# R7KA8P1AD register map
Vendor: Renesas Electronics Corporation; Series: RA8; File version: 1.10.02
CPU: CM85 r0p2, little endian, MPU, FPU, VTOR, 4 interrupt priority bits, 96 interrupts
Registers are 32-bit, read-write, reset 0x0 unless marked. A register's access mark holds for its fields unless they carry their own. Offsets are from the block's base; [hi:lo] are bit positions; {n}, {i} and the like mark numbered series; 'fields as' and 'values as' point back to an identical list; <NAME> marks a mode.

## BUS — Bus Control
Base 0x40003000
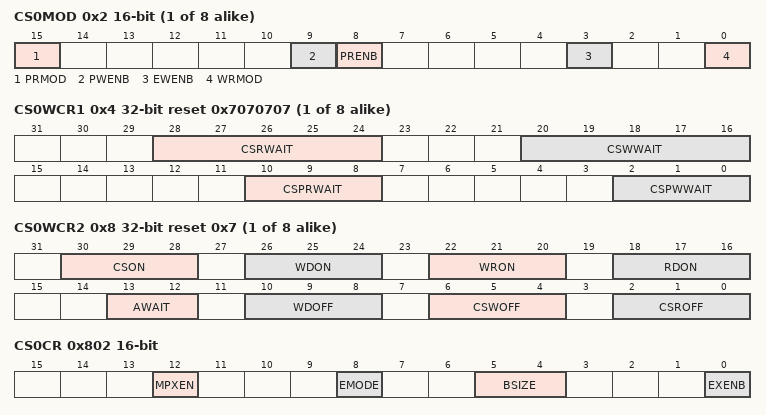
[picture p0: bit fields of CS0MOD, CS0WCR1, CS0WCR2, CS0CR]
{0x2+0x10*i} CS{i}MOD (i=0..7) 16-bit — CS{i} Mode Register (n = 0 to 7)
  [15] PRMOD — Page Read Access Mode Select
    0=Normal access compatible mode; 1=External data read continuous assertion mode
  [9] PWENB — Page Write Access Enable
    0=Disabled; 1=Enabled
  [8] PRENB — Page Read Access Enable
    0=Disabled; 1=Enabled
  [3] EWENB — External Wait Enable
    0=Disabled; 1=Enabled
  [0] WRMOD — Write Access Mode Select
    0=Byte strobe mode; 1=Single-write strobe mode
{0x4+0x10*i} CS{i}WCR1 (i=0..7) reset 0x7070707 — CS{i} Wait Control Register 1 (n = 0 to 7)
  [28:24] CSRWAIT — Normal Read Cycle Wait Select
  [20:16] CSWWAIT — Normal Write Cycle Wait Select
  [10:8] CSPRWAIT — Page Read Cycle Wait Select
  [2:0] CSPWWAIT — Page Write Cycle Wait Select
{0x8+0x10*i} CS{i}WCR2 (i=0..7) reset 0x7 — CS{i} Wait Control Register 2 (n = 0 to 7)
  [30:28] CSON — CS Assert Wait Select
  [26:24] WDON — Write Data Output Wait Select
  [22:20] WRON — WR Assert Wait Select
  [18:16] RDON — RD Assert Wait Select
  [13:12] AWAIT — Address Cycle Wait Select
  [10:8] WDOFF — Write Data Output Extension Cycle Select
  [6:4] CSWOFF — Write Access CS Extension Cycle Select
  [2:0] CSROFF — Read Access CS Extension Cycle Select
0x802 CS0CR 16-bit — CS0 Control Register
  [12] MPXEN — Address/Data Multiplexed I/O Interface Select
    0=Separate bus interface is selected for area n; 1=Address/data multiplexed I/O interface is selected for area n
  [8] EMODE — Endian Mode
    0=Little endian; 1=Big endian
  [5:4] BSIZE — External Bus Width Select
    0=16-bit bus space; 1=32-bit bus space; 2=8-bit bus space; other=Others (Setting prohibited)
  [0] EXENB — Operation Enable
    0=Disable operation; 1=Enable operation
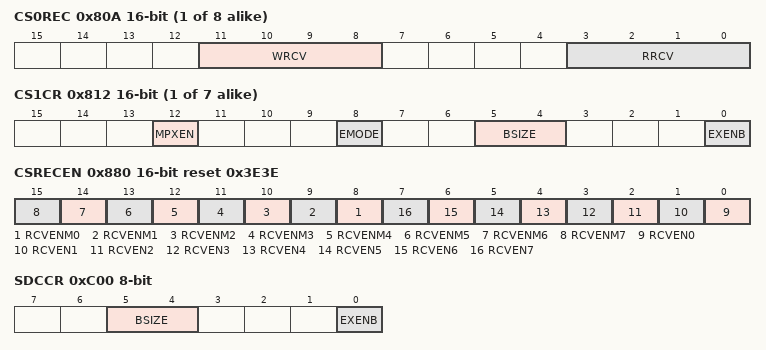
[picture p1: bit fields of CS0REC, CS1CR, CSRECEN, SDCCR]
{0x80A+0x10*i} CS{i}REC (i=0..7) 16-bit — CS{i} Recovery Cycle Register (n = 0 to 7)
  [11:8] WRCV — Write Recovery
  [3:0] RRCV — Read Recovery
{0x802+0x10*i} CS{i}CR (i=1..7) 16-bit — CS{i} Control Register
  fields as CS0CR
0x880 CSRECEN 16-bit reset 0x3E3E — CS Recovery Cycle Insertion Enable Register
  [all] fields
    0=Disabled; 1=Enabled
  [n+8] RCVENM{n} (n=0..7) — Multiplexed Bus Recovery Cycle Insertion Enable {n}
  [n] RCVEN{n} (n=0..7) — Separate Bus Recovery Cycle Insertion Enable {n}
0xC00 SDCCR 8-bit — SDC Control Register
  [5:4] BSIZE — SDRAM Bus Width Select
    values as CS0CR.BSIZE
  [0] EXENB — Operation Enable
    0=Disable; 1=Enable
0xC01 SDCMOD 8-bit — SDC Mode Register
  [0] EMODE — Endian Mode
    0=Little endian; 1=Big endian
0xC02 SDAMOD 8-bit — SDRAM Access Mode Register
  [0] BE — Continuous Access Enable
    0=Continuous access is disabled; 1=Continuous access is enabled
0xC10 SDSELF 8-bit — SDRAM Self-Refresh Control Register
  [0] SFEN — SDRAM Self-Refresh Enable
    0=Disable; 1=Enable
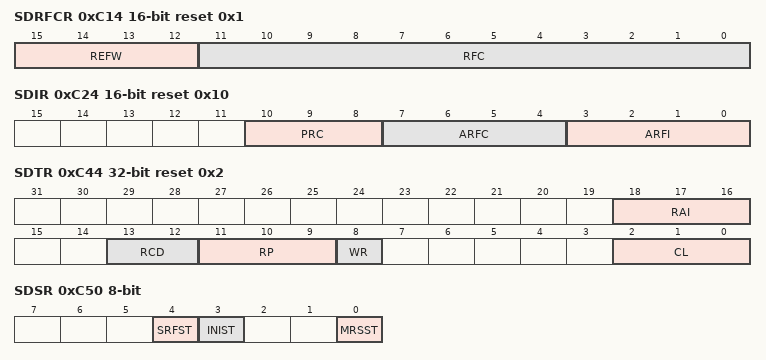
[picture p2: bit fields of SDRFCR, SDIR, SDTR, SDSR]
0xC14 SDRFCR 16-bit reset 0x1 — SDRAM Refresh Control Register
  [15:12] REFW — Auto-Refresh Cycle/Self-Refresh Clearing Cycle Count Setting
  [11:0] RFC — Auto-Refresh Request Interval Setting
0xC16 SDRFEN 8-bit — SDRAM Auto-Refresh Control Register
  [0] RFEN — Auto-Refresh Operation Enable
    0=Disable; 1=Enable
0xC20 SDICR 8-bit — SDRAM Initialization Sequence Control Register
  [0] INIRQ — Initialization Sequence Start
    0=Invalid; 1=Start initialization sequence
0xC24 SDIR 16-bit reset 0x10 — SDRAM Initialization Register
  [10:8] PRC — Initialization Precharge Cycle Count
  [7:4] ARFC — Initialization Auto-Refresh Count
  [3:0] ARFI — Initialization Auto-Refresh Interval
0xC40 SDADR 8-bit — SDRAM Address Register
  [1:0] MXC — Address Multiplex Select
    {v}={v+8}-bit shift (v=0..3)
0xC44 SDTR reset 0x2 — SDRAM Timing Register
  [18:16] RAI — Row Active Interval
    0=1 cycle; {v}={v+1} cycles (v=1..6); 7=Setting prohibited
  [13:12] RCD — Row Column Latency
    0=1 cycle; 1=2 cycles; 2=3 cycles; 3=4 cycles
  [11:9] RP — Row Precharge Interval
    0=1 cycle; {v}={v+1} cycles (v=1..7)
  [8] WR — Write Recovery Interval
    0=1 cycle; 1=2 cycles
  [2:0] CL — SDRAMC Column Latency
    0=Setting prohibited; 1=1 cycle; 2=2 cycles; 3=3 cycles; other=Others (Setting prohibited)
0xC48 SDMOD 16-bit — SDRAM Mode Register
  [14:0] MR — Mode Register Setting
0xC50 SDSR 8-bit ro — SDRAM Status Register
  [4] SRFST — Self-Refresh Transition/Recovery Status
    0=Transition/recovery not in progress; 1=Transition/recovery in progress
  [3] INIST — Initialization Status
    0=Initialization sequence not in progress; 1=Initialization sequence in progress
  [0] MRSST — Mode Register Setting Status
    0=Mode register setting not in progress; 1=Mode register setting in progress
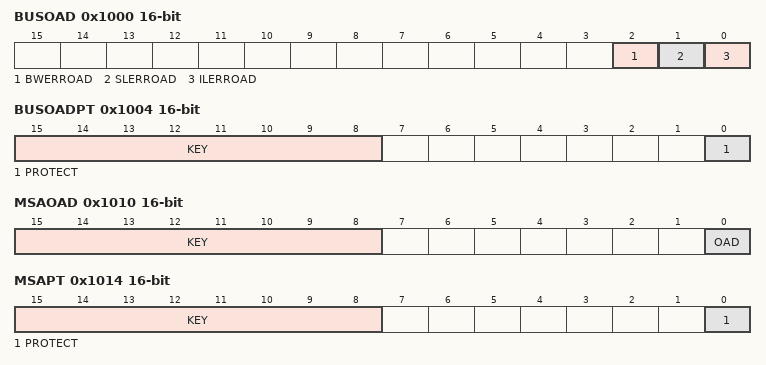
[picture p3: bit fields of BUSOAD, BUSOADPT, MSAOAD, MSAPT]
0x1000 BUSOAD 16-bit — BUS Operation After Detection Register
  [2] BWERROAD — Bufferable write error operation after detection
  [1] SLERROAD — Slave bus error operation after detection
  [0] ILERROAD — Illegal address access error operation after detection
0x1004 BUSOADPT 16-bit — BUS Operation After Detection Protect Register
  [15:8] KEY wo — Key code
  [0] PROTECT — Protection of register
    0=BUSOAD register writing is possible; 1=BUSOAD register writing is protected. Read is possible.
0x1010 MSAOAD 16-bit — Master Security Attribution Operation After Detection Register
  [15:8] KEY wo — Key Code
  [0] OAD — Operation after detection
    0=IRQ; 1=Reset
0x1014 MSAPT 16-bit — Master Security Attribution Protect Register
  [15:8] KEY wo — Key Code
  [0] PROTECT — Protection of register
    0=MSAOAD register writing is possible; 1=MSAOAD register writing is protected. Read is possible.
0x1100 BUSMABTGRAPHBI — Bus Master Arbitration Control Register
  [0] ARBS — Arbitration Select
    0=Fixed priority; 1=Round-robin
0x1200 BUSSABT1MRC0BI — Bus Slave Arbitration Control Register 1
  [1:0] ARBS — Arbitration Select
    0=Fixed priority; 1=Setting prohibited; 2=Combination of round-robin and fixed priority; 3=Round-robin
0x1208 BUSSABT0MRE0BI — Bus Slave Arbitration Control Register 0
  [0] ARBS — Arbitration Select for <slave>
    0=Fixed priority; 1=Round-robin
{0x1220+8i} BUSSABT0S{i}BI (i=0..3) — Bus Slave Arbitration Control Register 0
  fields as BUSSABT0MRE0BI
0x1250 BUSSABT0ECBI — Bus Slave Arbitration Control Register 0
  fields as BUSSABT0MRE0BI
0x1258 BUSSABT0OSPI0BI — Bus Slave Arbitration Control Register 0
  fields as BUSSABT0MRE0BI
0x1260 BUSSABT0OSPI1BI — Bus Slave Arbitration Control Register 0
  fields as BUSSABT0MRE0BI
0x1268 BUSSABT0CPU0SAHBI — Bus Slave Arbitration Control Register 0
  fields as BUSSABT0MRE0BI
0x1270 BUSSABT0CPU1TCMBI — Bus Slave Arbitration Control Register 0
  fields as BUSSABT0MRE0BI
0x1278 BUSSABT0PBBI — Bus Slave Arbitration Control Register 0
  fields as BUSSABT0MRE0BI
0x1280 BUSSABT0PABI — Bus Slave Arbitration Control Register 0
  fields as BUSSABT0MRE0BI
0x1288 BUSSABT0PIBI — Bus Slave Arbitration Control Register 0
  fields as BUSSABT0MRE0BI
0x1290 BUSSABT0PSBI — Bus Slave Arbitration Control Register 0
  fields as BUSSABT0MRE0BI
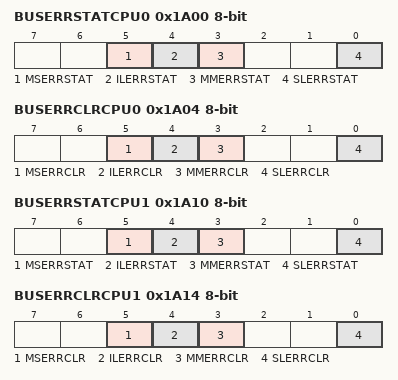
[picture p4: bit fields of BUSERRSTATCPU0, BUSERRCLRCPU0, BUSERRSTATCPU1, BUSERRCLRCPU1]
0x1A00 BUSERRSTATCPU0 8-bit ro — BUS Error Status Register
  [all] fields
    0=No error occurred; 1=Error occurred
  [5] MSERRSTAT — Master Security Attribution Unit Error Status
  [4] ILERRSTAT — Illegal Address Access Error Status
  [3] MMERRSTAT — Master MPU Error Status
  [0] SLERRSTAT — Slave Bus Error Status
0x1A04 BUSERRCLRCPU0 8-bit wo — BUS Error Clear Register
  [5] MSERRCLR — Master Security Attribution Unit Error Clear
    0=No effect; 1=Clear the BUSERRSTAT<Master Name>.MSERRSTAT flag
  [4] ILERRCLR — Illegal Address Access Error Clear
    0=No effect; 1=Clear the BUSERRSTAT<Master Name>.ILERRSTAT flag
  [3] MMERRCLR — Master MPU Error Clear
    0=No effect; 1=Clear the BUSERRSTAT<Master Name>.MMERRSTAT flag
  [0] SLERRCLR — Slave Bus Error Clear
    0=No effect; 1=Clear the BUSERRSTAT<Master Name>.SLERRSTAT flag
0x1A08 BUSIRQENCPU0 8-bit — BUS Error Interrupt Enable Register
  [0] EN — Interrupt enable after bus error detected
    0=Disable; 1=Enable
0x1A10 BUSERRSTATCPU1 8-bit ro — BUS Error Status Register
  fields as BUSERRSTATCPU0
0x1A14 BUSERRCLRCPU1 8-bit wo — BUS Error Clear Register
  fields as BUSERRCLRCPU0
0x1A18 BUSIRQENCPU1 8-bit — BUS Error Interrupt Enable Register
  fields as BUSIRQENCPU0
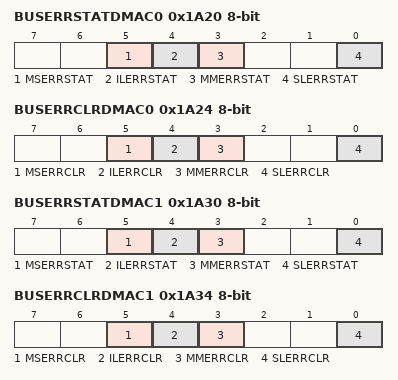
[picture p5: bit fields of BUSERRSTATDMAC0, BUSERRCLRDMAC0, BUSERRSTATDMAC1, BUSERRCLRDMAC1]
0x1A20 BUSERRSTATDMAC0 8-bit ro — BUS Error Status Register
  fields as BUSERRSTATCPU0
0x1A24 BUSERRCLRDMAC0 8-bit wo — BUS Error Clear Register
  fields as BUSERRCLRCPU0
0x1A28 BUSIRQENDMAC0 8-bit — BUS Error Interrupt Enable Register
  fields as BUSIRQENCPU0
0x1A30 BUSERRSTATDMAC1 8-bit ro — BUS Error Status Register
  fields as BUSERRSTATCPU0
0x1A34 BUSERRCLRDMAC1 8-bit wo — BUS Error Clear Register
  fields as BUSERRCLRCPU0
0x1A38 BUSIRQENDMAC1 8-bit — BUS Error Interrupt Enable Register
  fields as BUSIRQENCPU0
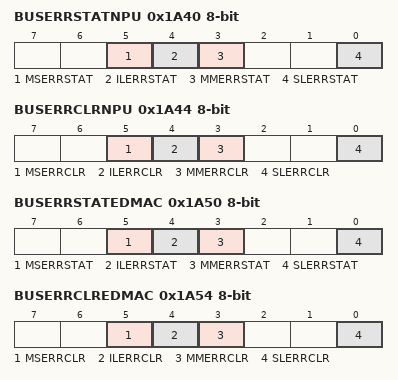
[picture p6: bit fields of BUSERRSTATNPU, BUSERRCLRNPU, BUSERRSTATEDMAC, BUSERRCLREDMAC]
0x1A40 BUSERRSTATNPU 8-bit ro — BUS Error Status Register
  fields as BUSERRSTATCPU0
0x1A44 BUSERRCLRNPU 8-bit wo — BUS Error Clear Register
  fields as BUSERRCLRCPU0
0x1A48 BUSIRQENNPU 8-bit — BUS Error Interrupt Enable Register
  fields as BUSIRQENCPU0
0x1A50 BUSERRSTATEDMAC 8-bit ro — BUS Error Status Register
  fields as BUSERRSTATCPU0
0x1A54 BUSERRCLREDMAC 8-bit wo — BUS Error Clear Register
  fields as BUSERRCLRCPU0
0x1A58 BUSIRQENEDMAC 8-bit — BUS Error Interrupt Enable Register
  fields as BUSIRQENCPU0
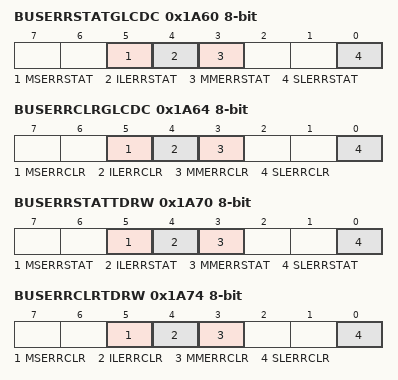
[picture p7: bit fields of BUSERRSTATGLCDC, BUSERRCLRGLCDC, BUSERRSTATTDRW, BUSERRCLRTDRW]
0x1A60 BUSERRSTATGLCDC 8-bit ro — BUS Error Status Register
  fields as BUSERRSTATCPU0
0x1A64 BUSERRCLRGLCDC 8-bit wo — BUS Error Clear Register
  fields as BUSERRCLRCPU0
0x1A68 BUSIRQENGLCDC 8-bit — BUS Error Interrupt Enable Register
  fields as BUSIRQENCPU0
0x1A70 BUSERRSTATTDRW 8-bit ro — BUS Error Status Register
  fields as BUSERRSTATCPU0
0x1A74 BUSERRCLRTDRW 8-bit wo — BUS Error Clear Register
  fields as BUSERRCLRCPU0
0x1A78 BUSIRQENTDRW 8-bit — BUS Error Interrupt Enable Register
  fields as BUSIRQENCPU0
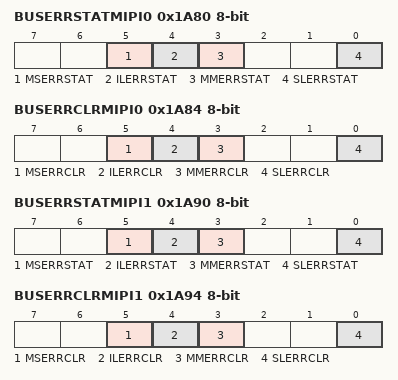
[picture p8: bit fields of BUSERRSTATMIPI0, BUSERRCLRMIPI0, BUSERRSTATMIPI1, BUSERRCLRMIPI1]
0x1A80 BUSERRSTATMIPI0 8-bit ro — BUS Error Status Register
  fields as BUSERRSTATCPU0
0x1A84 BUSERRCLRMIPI0 8-bit wo — BUS Error Clear Register
  fields as BUSERRCLRCPU0
0x1A88 BUSIRQENMIPI0 8-bit — BUS Error Interrupt Enable Register
  fields as BUSIRQENCPU0
0x1A90 BUSERRSTATMIPI1 8-bit ro — BUS Error Status Register
  fields as BUSERRSTATCPU0
0x1A94 BUSERRCLRMIPI1 8-bit wo — BUS Error Clear Register
  fields as BUSERRCLRCPU0
0x1A98 BUSIRQENMIPI1 8-bit — BUS Error Interrupt Enable Register
  fields as BUSIRQENCPU0
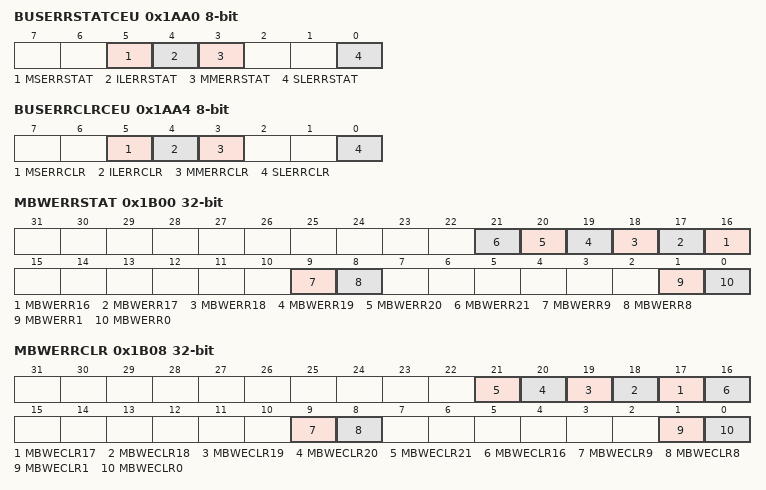
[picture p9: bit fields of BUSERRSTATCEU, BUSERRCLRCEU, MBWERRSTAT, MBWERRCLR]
0x1AA0 BUSERRSTATCEU 8-bit ro — BUS Error Status Register
  fields as BUSERRSTATCPU0
0x1AA4 BUSERRCLRCEU 8-bit wo — BUS Error Clear Register
  fields as BUSERRCLRCPU0
0x1AA8 BUSIRQENCEU 8-bit — BUS Error Interrupt Enable Register
  fields as BUSIRQENCPU0
0x1B00 MBWERRSTAT ro — Master Bufferable Write Error Status Register
  [n] MBWERR{n} (n=16..21) — Master Bufferable Write Error
    0=No bufferable write error in Master #{n}; 1=Bufferable write error occurs in Master #{n}
  [9] MBWERR9 — Master Bufferable Write Error
    0=No bufferable write error in Master #9; 1=Bufferable write error occurs in Master #9
  [8] MBWERR8 — Master Bufferable Write Error
    0=No bufferable write error in Master #8; 1=Bufferable write error occurs in Master #8
  [1] MBWERR1 — Master Bufferable Write Error
    0=No bufferable write error in Master #1; 1=Bufferable write error occurs in Master #1
  [0] MBWERR0 — Master Bufferable Write Error
    0=No bufferable write error in Master #0; 1=Bufferable write error occurs in Master #0
0x1B08 MBWERRCLR wo — Master Bufferable Write Error Clear Register
  [n] MBWECLR{n} (n=17..21) — Master Bufferable Write Error Clear
    0=No effect; 1=Clear the MBWERRSTAT.MBWERR{n} flag
  [16] MBWECLR16 — Master Bufferable Write Error Clear
    0=No effect; 1=Clears the MBWERRSTAT.MBWERR16 flag
  [9] MBWECLR9 — Master Bufferable Write Error Clear
    0=No effect; 1=Clear the MBWERRSTAT.MBWERR9 flag
  [8] MBWECLR8 — Master Bufferable Write Error Clear
    0=No effect; 1=Clear the MBWERRSTAT.MBWERR8 flag
  [1] MBWECLR1 — Master Bufferable Write Error Clear
    0=No effect; 1=Clear the MBWERRSTAT.MBWERR1 flag
  [0] MBWECLR0 — Master Bufferable Write Error Clear
    0=No effect; 1=Clear the MBWERRSTAT.MBWERR0 flag
